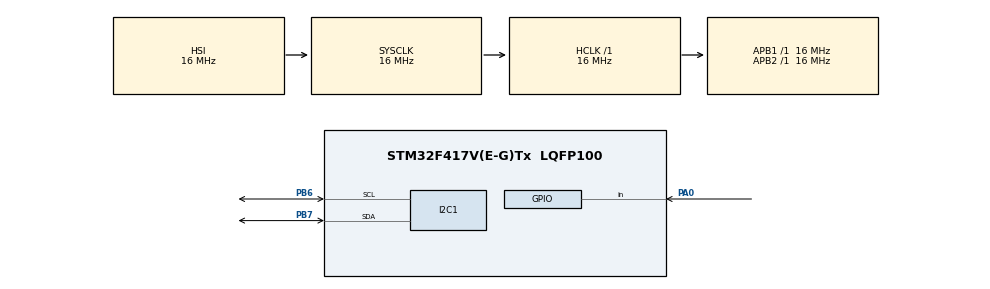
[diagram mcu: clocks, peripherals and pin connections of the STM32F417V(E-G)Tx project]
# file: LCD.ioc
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Mcu.Family=STM32F4
Mcu.Name=STM32F417V(E-G)Tx
Mcu.Package=LQFP100
NVIC.PriorityGroup=NVIC_PRIORITYGROUP_4
PA0-WKUP.Signal=GPIO_Input
PB6.Mode=I2C
PB6.Signal=I2C1_SCL
PB7.Mode=I2C
PB7.Signal=I2C1_SDA
ProjectManager.HeapSize=0x200
ProjectManager.StackSize=0x400
ProjectManager.TargetToolchain=MDK-ARM V5
RCC.AHBFreq_Value=16000000
RCC.APB1Freq_Value=16000000
RCC.APB2Freq_Value=16000000
RCC.CortexFreq_Value=16000000
RCC.HSE_VALUE=25000000
RCC.HSI_VALUE=16000000
RCC.LSE_VALUE=32768
RCC.SYSCLKFreq_VALUE=16000000
RCC.VCOOutputFreq_Value=192000000
board=LCD

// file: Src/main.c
/**
  ******************************************************************************
  * File Name          : main.c
  * Description        : Main program body
  ******************************************************************************
  ** This notice applies to any and all portions of this file
  * that are not between comment pairs USER CODE BEGIN and
  * USER CODE END. Other portions of this file, whether
  * inserted by the user or by software development tools
  * are owned by their respective copyright owners.
  *
  * COPYRIGHT(c) 2017 STMicroelectronics
  *
  * Redistribution and use in source and binary forms, with or without modification,
  * are permitted provided that the following conditions are met:
  *   1. Redistributions of source code must retain the above copyright notice,
  *      this list of conditions and the following disclaimer.
  *   2. Redistributions in binary form must reproduce the above copyright notice,
  *      this list of conditions and the following disclaimer in the documentation
  *      and/or other materials provided with the distribution.
  *   3. Neither the name of STMicroelectronics nor the names of its contributors
  *      may be used to endorse or promote products derived from this software
  *      without specific prior written permission.
  *
  * THIS SOFTWARE IS PROVIDED BY THE COPYRIGHT HOLDERS AND CONTRIBUTORS "AS IS"
  * AND ANY EXPRESS OR IMPLIED WARRANTIES, INCLUDING, BUT NOT LIMITED TO, THE
  * IMPLIED WARRANTIES OF MERCHANTABILITY AND FITNESS FOR A PARTICULAR PURPOSE ARE
  * DISCLAIMED. IN NO EVENT SHALL THE COPYRIGHT HOLDER OR CONTRIBUTORS BE LIABLE
  * FOR ANY DIRECT, INDIRECT, INCIDENTAL, SPECIAL, EXEMPLARY, OR CONSEQUENTIAL
  * DAMAGES (INCLUDING, BUT NOT LIMITED TO, PROCUREMENT OF SUBSTITUTE GOODS OR
  * SERVICES; LOSS OF USE, DATA, OR PROFITS; OR BUSINESS INTERRUPTION) HOWEVER
  * CAUSED AND ON ANY THEORY OF LIABILITY, WHETHER IN CONTRACT, STRICT LIABILITY,
  * OR TORT (INCLUDING NEGLIGENCE OR OTHERWISE) ARISING IN ANY WAY OUT OF THE USE
  * OF THIS SOFTWARE, EVEN IF ADVISED OF THE POSSIBILITY OF SUCH DAMAGE.
  *
  ******************************************************************************
  */
#include "main.h"
#include "stm32f4xx_hal.h"

I2C_HandleTypeDef hi2c1;

/* USER CODE BEGIN PV */
/* Private variables ---------------------------------------------------------*/
#define LCD_ADDRESS_W		0x7E
/* USER CODE END PV */

void SystemClock_Config(void);
static void MX_GPIO_Init(void);
static void MX_I2C1_Init(void);

/* USER CODE BEGIN PFP */
/* Private function prototypes -----------------------------------------------*/
/* LCD command function */
void lcd_send_cmd(char cmd)
{
	char data_u, data_l;
	uint8_t data_t[4];
	data_u = cmd&0xf0; //select upper nibble
	data_l = (cmd<<4)&0xf0; //select lower nibble
	data_t[0] = data_u|0x04;  //en=1, rs=0
	data_t[1] = data_u;  //en=0, rs=0
	data_t[2] = data_l|0x04;  //en=1, rs=0
	data_t[3] = data_l;  //en=0, rs=0
	HAL_I2C_Master_Transmit (&hi2c1, LCD_ADDRESS_W, data_t, 4, 50);
}

/* LCD data function */
void lcd_send_data (char data)
{
	char data_u, data_l;
	uint8_t data_t[4];
	data_u = data&0xf0;    // upper data nibble
	data_l = (data<<4)&0xf0;    // lower data nibble
	data_t[0] = data_u|0x05;  //en=1, rs=1
	data_t[1] = data_u|0x01;  //en=0, rs=1
	data_t[2] = data_l|0x05;  //en=1, rs=1
	data_t[3] = data_l|0x01;  //en=0, rs=1
	HAL_I2C_Master_Transmit (&hi2c1, LCD_ADDRESS_W, data_t, 4, 100);
}

/* LCD init */
void lcd_init(void)
{
	HAL_Delay(100);
	lcd_send_cmd(0x01); //clear display
	lcd_send_cmd(0x02);	//return home
	lcd_send_cmd(0x28); // 4 bits, 2 lines
	lcd_send_cmd(0x0c); // display on, cursor off
	//lcd_send_cmd(0x83); // set DDRAM position
}

/* LCD send string */
void lcd_send_string (char *str)
{
	while (*str) {
		lcd_send_data(*str++);
	}
}

void lcd_set_arrow (char *str, uint8_t *pos, uint8_t i)
{
	uint8_t brojac = 0;
	while(*str){
		lcd_send_cmd(*pos++);
		if (brojac == i){
			lcd_send_data(*str++);
		}else{
			lcd_send_data(' ');
			str++;
		}
		brojac++;
	}
}
/* USER CODE END PFP */

/* USER CODE BEGIN 0 */
_Bool toggle, lastState;
/* USER CODE END 0 */

int main(void)
{

  /* USER CODE BEGIN 1 */
	GPIO_PinState state;

	/* USER CODE END 1 */

  /* MCU Configuration----------------------------------------------------------*/

  /* Reset of all peripherals, Initializes the Flash interface and the Systick. */
  HAL_Init();

  /* USER CODE BEGIN Init */
	lastState = 0;
	toggle = 0;
	uint8_t pos = 0;
	char arrows[3] = {'^','>','^'};
	uint8_t arrow_pos[3] = {0xc2,0xc6,0xcd};
  /* USER CODE END Init */

  /* Configure the system clock */
  SystemClock_Config();

  /* Initialize all configured peripherals */
  MX_GPIO_Init();
  MX_I2C1_Init();

  /* USER CODE BEGIN 2 */
	lcd_init();

	lcd_send_string("PITCH:   YAW:   ");
	lcd_send_cmd(0xc7);
	lcd_send_string("SET");
	lcd_send_cmd(0x18);
	lcd_set_arrow(arrows,arrow_pos,pos);

  /* USER CODE END 2 */

  /* Infinite loop */
  while (1)
  {

	state = HAL_GPIO_ReadPin(GPIOA, GPIO_PIN_0);
	if(state == 1 & lastState == 0){
		if(toggle){
			toggle = 0;
		}else{
			toggle = 1;
		}
		lcd_set_arrow(arrows,arrow_pos,pos);
		pos++;
		if (pos == 3)
			pos = 0;
	}
	lastState = state;
  HAL_Delay(50);
	}

}

/** System Clock Configuration
*/
void SystemClock_Config(void)
{

  RCC_OscInitTypeDef RCC_OscInitStruct;
  RCC_ClkInitTypeDef RCC_ClkInitStruct;

    /**Configure the main internal regulator output voltage
    */
  __HAL_RCC_PWR_CLK_ENABLE();

  __HAL_PWR_VOLTAGESCALING_CONFIG(PWR_REGULATOR_VOLTAGE_SCALE1);

    /**Initializes the CPU, AHB and APB busses clocks
    */
  RCC_OscInitStruct.OscillatorType = RCC_OSCILLATORTYPE_HSI;
  RCC_OscInitStruct.HSIState = RCC_HSI_ON;
  RCC_OscInitStruct.HSICalibrationValue = 16;
  RCC_OscInitStruct.PLL.PLLState = RCC_PLL_NONE;
  if (HAL_RCC_OscConfig(&RCC_OscInitStruct) != HAL_OK)
  {
    _Error_Handler(__FILE__, __LINE__);
  }

    /**Initializes the CPU, AHB and APB busses clocks
    */
  RCC_ClkInitStruct.ClockType = RCC_CLOCKTYPE_HCLK|RCC_CLOCKTYPE_SYSCLK
                              |RCC_CLOCKTYPE_PCLK1|RCC_CLOCKTYPE_PCLK2;
  RCC_ClkInitStruct.SYSCLKSource = RCC_SYSCLKSOURCE_HSI;
  RCC_ClkInitStruct.AHBCLKDivider = RCC_SYSCLK_DIV1;
  RCC_ClkInitStruct.APB1CLKDivider = RCC_HCLK_DIV1;
  RCC_ClkInitStruct.APB2CLKDivider = RCC_HCLK_DIV1;

  if (HAL_RCC_ClockConfig(&RCC_ClkInitStruct, FLASH_LATENCY_0) != HAL_OK)
  {
    _Error_Handler(__FILE__, __LINE__);
  }

    /**Configure the Systick interrupt time
    */
  HAL_SYSTICK_Config(HAL_RCC_GetHCLKFreq()/1000);

    /**Configure the Systick
    */
  HAL_SYSTICK_CLKSourceConfig(SYSTICK_CLKSOURCE_HCLK);

  /* SysTick_IRQn interrupt configuration */
  HAL_NVIC_SetPriority(SysTick_IRQn, 0, 0);
}

/* I2C1 init function */
static void MX_I2C1_Init(void)
{

  hi2c1.Instance = I2C1;
  hi2c1.Init.ClockSpeed = 100000;
  hi2c1.Init.DutyCycle = I2C_DUTYCYCLE_2;
  hi2c1.Init.OwnAddress1 = 0;
  hi2c1.Init.AddressingMode = I2C_ADDRESSINGMODE_7BIT;
  hi2c1.Init.DualAddressMode = I2C_DUALADDRESS_DISABLE;
  hi2c1.Init.OwnAddress2 = 0;
  hi2c1.Init.GeneralCallMode = I2C_GENERALCALL_DISABLE;
  hi2c1.Init.NoStretchMode = I2C_NOSTRETCH_DISABLE;
  if (HAL_I2C_Init(&hi2c1) != HAL_OK)
  {
    _Error_Handler(__FILE__, __LINE__);
  }

}

/** Configure pins as
        * Analog
        * Input
        * Output
        * EVENT_OUT
        * EXTI
*/
static void MX_GPIO_Init(void)
{

  GPIO_InitTypeDef GPIO_InitStruct;

  /* GPIO Ports Clock Enable */
  __HAL_RCC_GPIOA_CLK_ENABLE();
  __HAL_RCC_GPIOB_CLK_ENABLE();

  /*Configure GPIO pin : PA0 */
  GPIO_InitStruct.Pin = GPIO_PIN_0;
  GPIO_InitStruct.Mode = GPIO_MODE_INPUT;
  GPIO_InitStruct.Pull = GPIO_NOPULL;
  HAL_GPIO_Init(GPIOA, &GPIO_InitStruct);

}

void _Error_Handler(char * file, int line)
{
  while(1)
  {
  }
}

/************************ (C) COPYRIGHT STMicroelectronics *****END OF FILE****/
